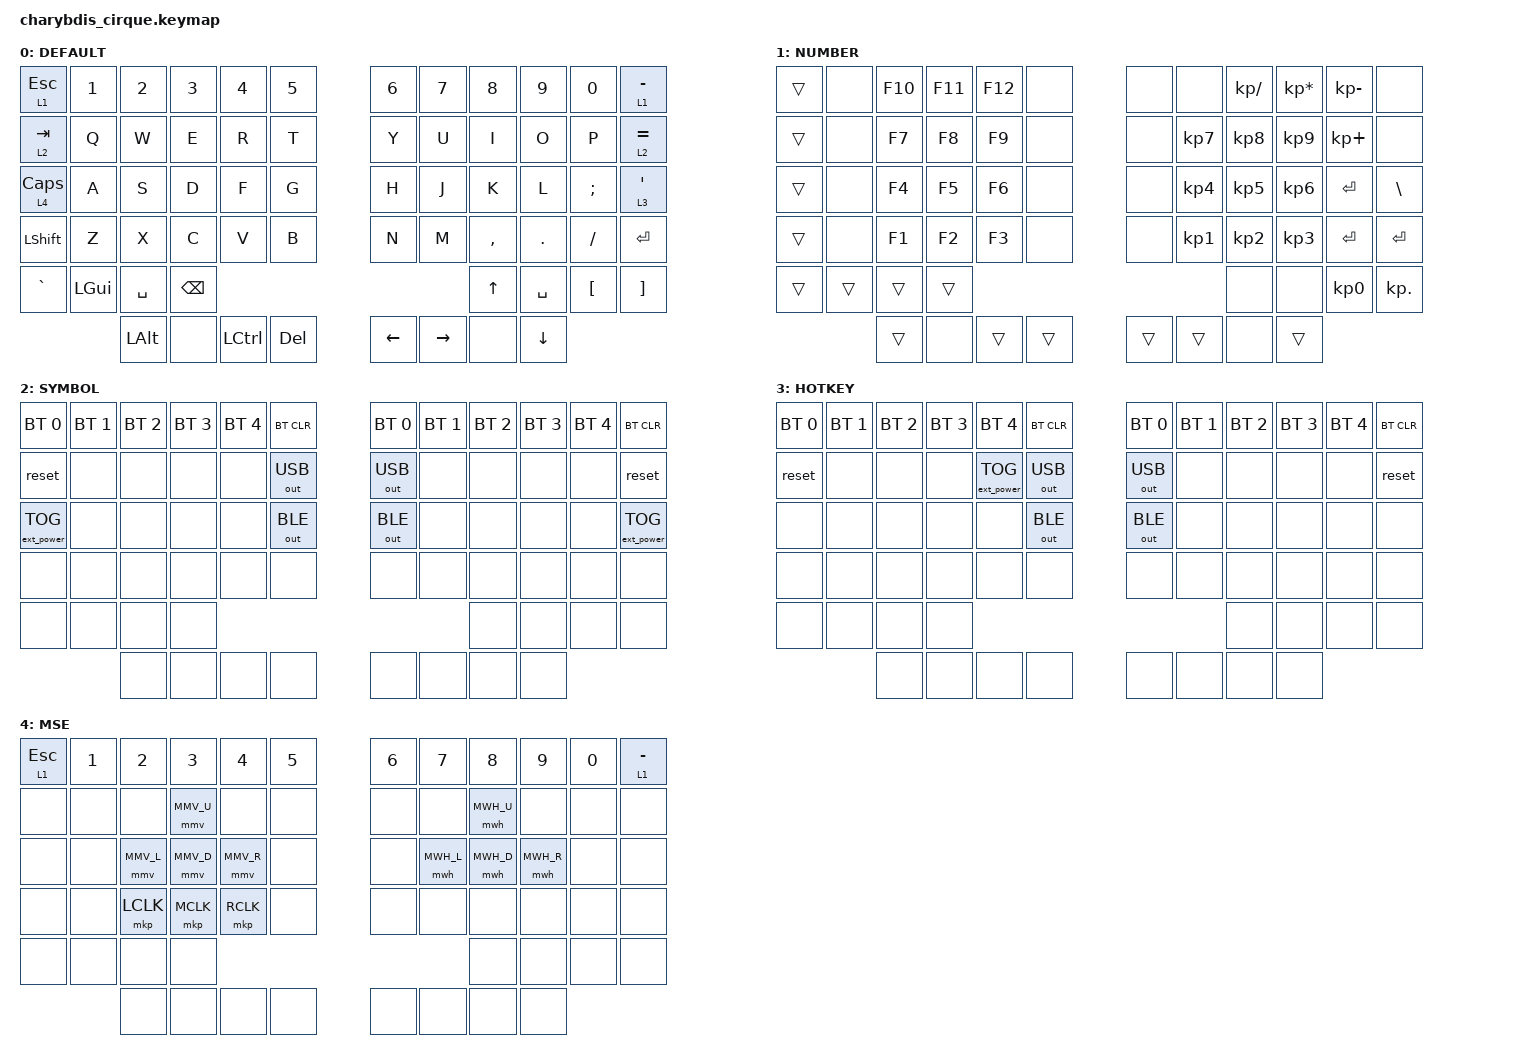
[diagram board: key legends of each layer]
#include <behaviors.dtsi>
#include <dt-bindings/zmk/mouse.h>
#include <dt-bindings/zmk/keys.h>
#include <dt-bindings/zmk/bt.h>
#include <dt-bindings/zmk/outputs.h>
#include <dt-bindings/zmk/ext_power.h>


// mouse move settings
#define MMV_U MOVE_VERT(-650)
#define MMV_D MOVE_VERT(650)
#define MMV_L MOVE_HOR(-650)
#define MMV_R MOVE_HOR(650)

&mmv {    
        time-to-max-speed-ms = <500>;
        acceleration-exponent=<1>;
};

// mouse wheel settings
#define MWH_U SCROLL_VERT(15)
#define MWH_D SCROLL_VERT(-15)
#define MWH_L SCROLL_HOR(-15)
#define MWH_R SCROLL_HOR(15)

&mwh {    
        time-to-max-speed-ms = <2000>;
        acceleration-exponent=<0>;
};

#define DEFAULT 0
#define NUMBER  1
#define SYMBOL  2
#define HOTKEY  3
#define MSE     4

#define AS(keycode) &as LS(keycode) keycode

/{

        behaviors {
        td0: tap_dance_0 {
            compatible = "zmk,behavior-tap-dance";
            label = "TAP_DANCE_0";
            #binding-cells = <0>;
            tapping-term-ms = <200>;
            bindings = <&kp ESC>, <&kp TAB>;
        };
    };  

         behaviors {
       as: auto_shift {
        compatible = "zmk,behavior-hold-tap";
        label = "AUTO_SHIFT";
        #binding-cells = <2>;
        tapping-term-ms = <200>;
        quick-tap-ms = <0>;
        flavor = "tap-preferred";
        bindings = <&kp>, <&kp>;
                };             
modcp: mod_copy {
        compatible = "zmk,behavior-mod-morph";
        label = "MOD_COPY";
        #binding-cells = <0>;
        bindings = <&as LS(C) C>, <&kp C>;
        mods = <(LGUI | RGUI)>;
};
        };


    macros {
        macro_phone: macro_phone {
            // 1351
            label = "MACRO_PHONE";
            compatible = "zmk,behavior-macro";
            #binding-cells = <0>;
            bindings
                = < &kp N1 &kp N3 &kp N5  &kp N1>
                ;
        };
        macro_email_q: macro_email_q {
            // 2894512440@qq.com
            label = "MACRO_EMAIL_QQ";
            compatible = "zmk,behavior-macro";
            #binding-cells = <0>;
            bindings 
                = < &kp N2 &kp N8 &kp N9 &kp N4 &kp N5 &kp  N1 &kp N2 &kp N4 &kp N4 &kp N0 
                    &kp AT &kp Q &kp Q &kp DOT  &kp C &kp O &kp M>
                ;
        };
        macro_email_g: macro_email_g {
            // 135115
            compatible = "zmk,behavior-macro";
            label = "MACRO_EMAIL_GMAIL";
            #binding-cells = <0>;
            bindings
                = < &kp N1 &kp N3 &kp N5  &kp N1 &kp N1 &kp N5 > ;
        };
       
    };
    
     combos {
        compatible = "zmk,combos";
        combo_esc {
            timeout-ms = <50>;
            key-positions = <2 38>;
            bindings = <&kp TAB>;
        };
             combo_rgui {
            timeout-ms = <50>;
            key-positions = <3 38>;
            bindings = <&kp CAPS>;
        };
        
         combo_LSHFT {
            timeout-ms = <50>;
            key-positions = <14 38>;
            bindings = <&kp  LSHFT>;
        };
       
         combo_2 {
            timeout-ms = <50>;
            key-positions = <15 38>;
            bindings = <&kp N2 >;
        };
         combo_3 {
            timeout-ms = <50>;
            key-positions = <16 38>;
            bindings = <&kp N3>;
        };
            combo_LGUI {
            timeout-ms = <50>;
            key-positions = <26 38>;
            bindings = <&kp LGUI>;
        };
              combo_GUI {
            timeout-ms = <50>;
            key-positions = <27 38>;
            bindings = <&tog 1>;
        };
                  combo_G {
            timeout-ms = <50>;
            key-positions = <14 39>;
            bindings = <&mo 4>;
        };
                  combo_GU {
            timeout-ms = <50>;
            key-positions = <14 39>;
            bindings = <&mo 2>;
        };
                      combo_m {
            timeout-ms = <50>;
            key-positions = <21 41>;
            bindings = <&mo 4>;
        };
        
  
   };



    keymap {
       compatible = "zmk,keymap";
       default_layer {
            label = "DEFAULT";
            bindings = <
&lt 1 ESC &kp N1 &kp N2 &kp N3 &kp N4 &kp N5           &kp N6  &kp N7  &kp N8  &kp N9  &kp N0   &lt 1  MINUS
&lt 2 TAB    &kp Q  &kp W    &kp E   &kp R   &kp T        &kp Y  &kp U     &kp I     &kp O    &kp P    &lt 2 EQUAL
&lt 4 CAPS  &kp A  &kp S    &kp D    &kp F     &kp G               &kp H  &kp J     &kp K     &kp L    &kp SEMI &lt 3 SQT
&kp LSHFT &kp Z  &kp X    &kp C    &kp V     &kp B                &kp N  &kp M     &kp COMMA &kp DOT  &kp FSLH  &kp ENTER 
&kp GRAVE  &kp LGUI  &kp SPACE &kp BSPC                    &kp UP &kp SPACE    &kp LBKT  &kp RBKT          
&kp LALT &none	&kp LCTRL 	&kp DEL 	       &kp LEFT   &kp RIGHT &none &kp DOWN  
            >;
sensor-bindings = <&inc_dec_kp C_VOL_UP C_VOL_DN &inc_dec_kp RIGHT LEFT>;
                trackball-bindings = <&tmv>;
        };  


          number_layer {
            label = "NUMBER";
            bindings = <
            
    &trans  &none &kp F10 &kp F11   &kp F12 &none             &none  &none    &kp KP_SLASH &kp KP_MULTIPLY   &kp KP_MINUS  &none
    &trans  &none &kp F7  &kp F8   &kp F9  &none              &none &kp KP_N7  &kp KP_N8  &kp KP_N9 &kp KP_PLUS  &none 
    &trans   &none  &kp F4   &kp F5   &kp F6  &none           &none &kp KP_N4  &kp KP_N5  &kp KP_N6 &kp ENTER    &kp BSLH
   &trans  &none  &kp F1    &kp F2    &kp F3    &none           &none &kp KP_N1 &kp KP_N2 &kp KP_N3 &kp ENTER  &kp ENTER 
   &trans     &trans     &trans    &trans                                  &none &none	&kp KP_N0 &kp KP_DOT	
      &trans  &none    &trans    &trans                                       &trans     &trans      &none    &trans     
            >;
               trackball-bindings = <&tsl>;    
        };

        symbol_layer {
            label = "SYMBOL";
            bindings = <
&bt BT_SEL 0	&bt BT_SEL 1	&bt BT_SEL 2	&bt BT_SEL 3 &bt BT_SEL 4 &bt BT_CLR 	&bt BT_SEL 0	&bt BT_SEL 1	&bt BT_SEL 2	&bt BT_SEL 3 &bt BT_SEL 4 &bt BT_CLR 
&reset 	&none	&none	&none	&none	&out OUT_USB	&out OUT_USB	&none	&none	&none	&none	&reset 
&ext_power EP_TOG	&none	&none	&none	&none	&out OUT_BLE	&out OUT_BLE	&none	&none	&none	&none	&ext_power EP_TOG
	&none	&none	&none	&none	&none	&none	&none	&none	&none	&none	&none	&none
		&none	&none 	&none	&none	&none	&none	&none	&none		
		&none	&none	&none	&none	&none	&none	&none	&none	                                                                                       
         >;
                   trackball-bindings = <&tmv_fine>;
        };


        hotkey_layer {
            label = "HOTKEY";
            bindings = <
&bt BT_SEL 0	&bt BT_SEL 1	&bt BT_SEL 2	&bt BT_SEL 3 &bt BT_SEL 4 &bt BT_CLR 	&bt BT_SEL 0	&bt BT_SEL 1	&bt BT_SEL 2	&bt BT_SEL 3 &bt BT_SEL 4 &bt BT_CLR 
&reset 	&none	&none	&none	&ext_power EP_TOG	&out OUT_USB	&out OUT_USB	&none	&none	&none	&none	&reset 
&none	&none	&none	&none	&none	&out OUT_BLE	&out OUT_BLE	&none	&none	&none	&none	&none
	&none	&none	&none	&none	&none	&none	&none	&none	&none	&none	&none	&none
		&none	&none 	&none	&none	&none	&none	&none	&none		
		&none	&none	&none	&none	&none	&none	&none	&none	                                                    
            >;
                 trackball-bindings = <&tmv_x>;
        };
        
            mouse_layer {
            label = "MSE";
            bindings = <
    &lt 1 ESC &kp N1 &kp N2 &kp N3 &kp N4 &kp N5           &kp N6  &kp N7  &kp N8  &kp N9  &kp N0   &lt 1  MINUS        
 &none &none  &none       &mmv MMV_U  &none       &none       &none  &none       &mwh MWH_U  &none       &none  &none
            &none     &none  &mmv MMV_L  &mmv MMV_D  &mmv MMV_R  &none       &none  &mwh MWH_L  &mwh MWH_D  &mwh MWH_R  &none  &none
&none &none &mkp LCLK &mkp MCLK &mkp RCLK &none                                            &none &none &none &none &none &none
   &none &none &none &none                                                              &none &none &none &none
   &none &none &none &none                                                              &none &none &none &none                                                     
            >;
                trackball-bindings = <&tmv_x>;
        };
        
        
        
   };
};
